# NUC400_v1 register map
File version: 1.0
Registers are 32-bit, read-write, reset 0x0 unless marked. A register's access mark holds for its fields unless they carry their own. Offsets are from the block's base; [hi:lo] are bit positions; {n}, {i} and the like mark numbered series.

## PS2 — PS2 Register Map
Base 0x400E0000
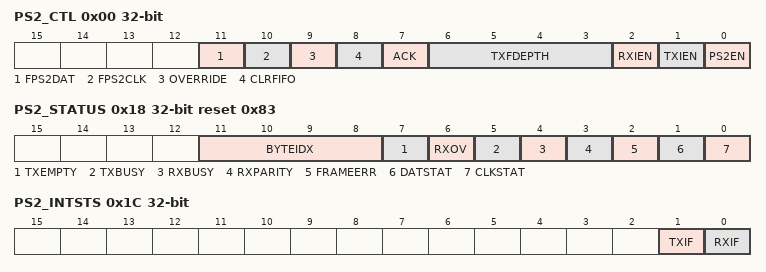
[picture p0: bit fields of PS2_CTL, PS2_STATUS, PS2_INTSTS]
0x00 PS2_CTL — PS/2 Control Register
  [11] FPS2DAT — Force DATSTAT Line. It forces DATSTAT high or low regardless of the internal state of the device controller if OVERRIDE is set to high.
    0=Force DATSTAT low; 1=Force DATSTAT high
  [10] FPS2CLK — Force CLKSTAT Line. It forces CLKSTAT line high or low regardless of the internal state of the device controller if OVERRIDE is set to high.
    0=Force CLKSTAT line low; 1=Force CLKSTAT line high
  [9] OVERRIDE — Software Override PS/2 CLK/DATA Pin State
    0=CLKSTAT and DATSTAT pins are controlled by internal state machine; 1=CLKSTAT and DATSTAT pins are controlled by software
  [8] CLRFIFO — Clear TX FIFO. Write 1 to this bit to terminate device to host transmission. The TXEMPTY(PS2_STATUS[7]) bit will be set to 1 and pointer BYTEIDEX(PS2_STATUS[11:8]) is reset to 0 regardless there is residue data in buffer or not. The buffer content is not been cleared.
    0=Not active; 1=Clear FIFO
  [7] ACK — Acknowledge Enable Bit
    0=Always sends acknowledge to host at 12th clock for host to device communication; 1=If parity error or stop bit is not received correctly, acknowledge bit will not be sent to host at 12th clock
  [6:3] TXFDEPTH — Transmit Data FIFO Depth. There is 16-byte buffer for data transmit. Software can define the FIFO depth from 1 to 16 bytes depending on the application.
    0=1 byte; 1=2 bytes; 14=15 bytes; 15=16 bytes
  [2] RXIEN — Receive Interrupt Enable Bit
    0=Data receive complete interrupt Disabled; 1=Data receive complete interrupt Enabled
  [1] TXIEN — Transmit Interrupt Enable Bit
    0=Data transmit complete interrupt Disabled; 1=Data transmit complete interrupt Enabled
  [0] PS2EN — PS/2 Device Enable Bit. Enable PS/2 device controller.
    0=Disabled; 1=Enabled
{0x4+4i} PS2_TXDAT{i} (i=0..3) — PS/2 Transmit DATA Register {i}
  [31:0] DAT — Transmit Data. Write data to this register starts device to host communication if bus is in IDLE state. Software must enable PS2EN(PS2_CTL[0]) before writing data to TX buffer.
0x14 PS2_RXDAT ro — PS/2 Receive DATA Register
  [7:0] DAT — Received Data. For host to device communication, after acknowledge bit is sent, the received data is copied from receive shift register to PS2_RXDAT register. CPU must read this register before next byte reception complete; otherwise, the data will be overwritten and RXOV(PS2_STATUS[6]) bit will be set to 1.
0x18 PS2_STATUS reset 0x83
  [11:8] BYTEIDX — Byte Index
  [7] TXEMPTY — TX FIFO Empty. When software writes any data to PS2_TXDAT0-3 the TXEMPTY bit is cleared to 0 immediately if PS2EN is enabled. When transmitted data byte number is equal to FIFODEPTH then TXEMPTY bit is set to 1. Note: This bit is read only.
    0=There is data to be transmitted; 1=FIFO is empty
  [6] RXOV — RX Buffer Overwrite. Note: Write 1 to clear this bit.
    0=No overwrite; 1=Data in PS2_RXDAT register is overwritten by new received data
  [5] TXBUSY — Transmit Busy. This bit indicates that the PS/2 device is currently sending data. Note: This bit is read only.
    0=Idle; 1=Currently sending data
  [4] RXBUSY — Receive Busy. This bit indicates that the PS/2 device is currently receiving data. Note: This bit is read only.
    0=Idle; 1=Currently receiving data
  [3] RXPARITY — Received Parity. This bit reflects the parity bit for the last received data byte (odd parity). Note: This bit is read only.
  [2] FRAMEERR — Frame Error. For host to device communication, if STOP bit (logic 1) is not received it is a frame error. If frame error occurs, DATA line may keep at low state after 12th clock. At this moment, software overrides CLKSTAT to send clock till DATSTAT release to high state. After that, device sends a "Resend" command to host. Note: Write 1 to clear this bit.
    0=No frame error; 1=Frame error occurred
  [1] DATSTAT — DATA Pin State. This bit reflects the status of the DATSTAT line after synchronizing and sampling.
  [0] CLKSTAT — CLK Pin State. This bit reflects the status of the CLKSTAT line after synchronizing.
0x1C PS2_INTSTS — PS/2 Interrupt Status Register
  [1] TXIF — Transmit Interrupt. This bit is set to 1 after STOP bit is transmitted. Interrupt occurs if TXIEN(PS2_CTL[1]) bit is set to 1. Note: Write 1 to clear this bit to 0.
    0=No interrupt; 1=Transmit interrupt occurred
  [0] RXIF — Receive Interrupt. This bit is set to 1 when acknowledge bit is sent for Host to device communication. Interrupt occurs if RXIEN(PS2_CTL[2]) bit is set to 1. Note: Write 1 to clear this bit to 0.
    0=No interrupt; 1=Receive interrupt occurred
